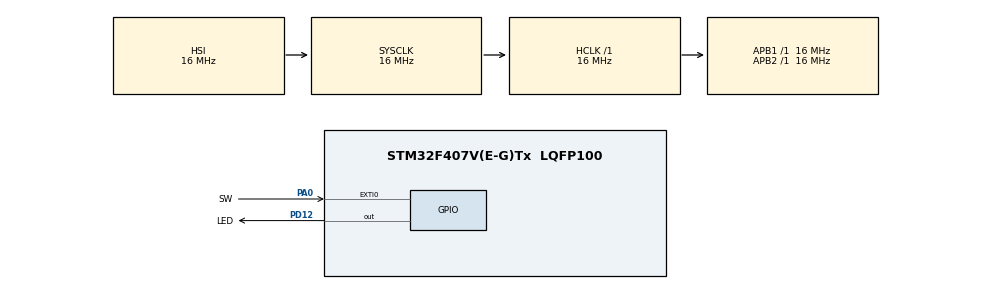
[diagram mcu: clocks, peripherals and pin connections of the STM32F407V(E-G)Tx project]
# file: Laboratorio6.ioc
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Mcu.Family=STM32F4
Mcu.Name=STM32F407V(E-G)Tx
Mcu.Package=LQFP100
NVIC.EXTI0_IRQn=true\:0\:0\:false\:false\:true\:true\:true\:true
NVIC.PriorityGroup=NVIC_PRIORITYGROUP_4
PA0-WKUP.GPIO_Label=SW
PA0-WKUP.GPIO_ModeDefaultEXTI=GPIO_MODE_IT_FALLING
PA0-WKUP.Signal=GPXTI0
PD12.GPIO_Label=LED
PD12.Signal=GPIO_Output
ProjectManager.HeapSize=0x200
ProjectManager.StackSize=0x400
ProjectManager.TargetToolchain=STM32CubeIDE
RCC.AHBFreq_Value=16000000
RCC.APB1Freq_Value=16000000
RCC.APB2Freq_Value=16000000
RCC.CortexFreq_Value=16000000
RCC.HSE_VALUE=25000000
RCC.HSI_VALUE=16000000
RCC.LSE_VALUE=32768
RCC.SYSCLKFreq_VALUE=16000000
RCC.VCOOutputFreq_Value=192000000
board=custom

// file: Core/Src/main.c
/* USER CODE BEGIN Header */
/**
 ******************************************************************************
 * @file           : main.c
 * @brief          : Main program body
 ******************************************************************************
 * @attention
 *
 * Copyright (c) 2026 STMicroelectronics.
 * All rights reserved.
 *
 * This software is licensed under terms that can be found in the LICENSE file
 * in the root directory of this software component.
 * If no LICENSE file comes with this software, it is provided AS-IS.
 *
 ******************************************************************************
 */
/* USER CODE END Header */
#include "main.h"

/* USER CODE BEGIN Includes */
#include "Statechart_required.h"
#include <stdbool.h>
/* USER CODE END Includes */

/* USER CODE BEGIN PD */
#define T_REBOTE_MS 50U
/* USER CODE END PD */

/* USER CODE BEGIN PV */
Statechart mi_maquina;
volatile bool sw = false;
volatile uint32_t last_sw = 0;

uint32_t sc_timer_start = 0;
uint32_t sc_timer_delay = 0;
bool sc_timer_active = false;
sc_eventid sc_active_evid = NULL;
/* USER CODE END PV */

void SystemClock_Config(void);
static void MX_GPIO_Init(void);

int main(void)
{

	/* USER CODE BEGIN 1 */
	uint32_t current_time = 0;
	/* USER CODE END 1 */

	/* MCU Configuration--------------------------------------------------------*/

	/* Reset of all peripherals, Initializes the Flash interface and the Systick. */
	HAL_Init();

	/* Configure the system clock */
	SystemClock_Config();

	/* Initialize all configured peripherals */
	MX_GPIO_Init();
	/* USER CODE BEGIN 2 */
	statechart_init(&mi_maquina);
	statechart_enter(&mi_maquina);
	/* USER CODE END 2 */

	/* Infinite loop */
	while (1)
	{
		if(sc_timer_active && ((HAL_GetTick()-sc_timer_start)>= sc_timer_delay))
		{
			sc_timer_active = false;
			statechart_raise_time_event(&mi_maquina, sc_active_evid);
		}
		if(sw)
		{
			current_time = HAL_GetTick();
			if(current_time-last_sw > T_REBOTE_MS)
			{
				if(HAL_GPIO_ReadPin(SW_GPIO_Port, SW_Pin) == GPIO_PIN_RESET)
				{
					statechartIface_raise_pulsacion(&mi_maquina);
				}
				sw = false;
				__HAL_GPIO_EXTI_CLEAR_IT(SW_Pin);
				HAL_NVIC_ClearPendingIRQ(EXTI0_IRQn);
				HAL_NVIC_EnableIRQ(EXTI0_IRQn);
			}
		}
		bool encender_led = statechartIface_get_led_encendido(&mi_maquina);
		if (encender_led)
		{
			HAL_GPIO_WritePin(LED_GPIO_Port, LED_Pin, GPIO_PIN_SET);
		}
		else
		{
			HAL_GPIO_WritePin(LED_GPIO_Port, LED_Pin, GPIO_PIN_RESET);
		}
	}
}

void SystemClock_Config(void)
{
	RCC_OscInitTypeDef RCC_OscInitStruct = {0};
	RCC_ClkInitTypeDef RCC_ClkInitStruct = {0};

	/** Configure the main internal regulator output voltage
	 */
	__HAL_RCC_PWR_CLK_ENABLE();
	__HAL_PWR_VOLTAGESCALING_CONFIG(PWR_REGULATOR_VOLTAGE_SCALE1);

	/** Initializes the RCC Oscillators according to the specified parameters
	 * in the RCC_OscInitTypeDef structure.
	 */
	RCC_OscInitStruct.OscillatorType = RCC_OSCILLATORTYPE_HSI;
	RCC_OscInitStruct.HSIState = RCC_HSI_ON;
	RCC_OscInitStruct.HSICalibrationValue = RCC_HSICALIBRATION_DEFAULT;
	RCC_OscInitStruct.PLL.PLLState = RCC_PLL_NONE;
	if (HAL_RCC_OscConfig(&RCC_OscInitStruct) != HAL_OK)
	{
		Error_Handler();
	}

	/** Initializes the CPU, AHB and APB buses clocks
	 */
	RCC_ClkInitStruct.ClockType = RCC_CLOCKTYPE_HCLK|RCC_CLOCKTYPE_SYSCLK
			|RCC_CLOCKTYPE_PCLK1|RCC_CLOCKTYPE_PCLK2;
	RCC_ClkInitStruct.SYSCLKSource = RCC_SYSCLKSOURCE_HSI;
	RCC_ClkInitStruct.AHBCLKDivider = RCC_SYSCLK_DIV1;
	RCC_ClkInitStruct.APB1CLKDivider = RCC_HCLK_DIV1;
	RCC_ClkInitStruct.APB2CLKDivider = RCC_HCLK_DIV1;

	if (HAL_RCC_ClockConfig(&RCC_ClkInitStruct, FLASH_LATENCY_0) != HAL_OK)
	{
		Error_Handler();
	}
}

static void MX_GPIO_Init(void)
{
	GPIO_InitTypeDef GPIO_InitStruct = {0};

	/* GPIO Ports Clock Enable */
	__HAL_RCC_GPIOA_CLK_ENABLE();
	__HAL_RCC_GPIOD_CLK_ENABLE();

	/*Configure GPIO pin Output Level */
	HAL_GPIO_WritePin(LED_GPIO_Port, LED_Pin, GPIO_PIN_RESET);

	/*Configure GPIO pin : SW_Pin */
	GPIO_InitStruct.Pin = SW_Pin;
	GPIO_InitStruct.Mode = GPIO_MODE_IT_FALLING;
	GPIO_InitStruct.Pull = GPIO_NOPULL;
	HAL_GPIO_Init(SW_GPIO_Port, &GPIO_InitStruct);

	/*Configure GPIO pin : LED_Pin */
	GPIO_InitStruct.Pin = LED_Pin;
	GPIO_InitStruct.Mode = GPIO_MODE_OUTPUT_PP;
	GPIO_InitStruct.Pull = GPIO_NOPULL;
	GPIO_InitStruct.Speed = GPIO_SPEED_FREQ_LOW;
	HAL_GPIO_Init(LED_GPIO_Port, &GPIO_InitStruct);

	/* EXTI interrupt init*/
	HAL_NVIC_SetPriority(EXTI0_IRQn, 0, 0);
	HAL_NVIC_EnableIRQ(EXTI0_IRQn);

}

/* USER CODE BEGIN 4 */
void HAL_GPIO_EXTI_Callback(uint16_t GPIO_Pin)
{
	if(GPIO_Pin == SW_Pin)
	{
		HAL_NVIC_DisableIRQ(EXTI0_IRQn);
		last_sw = HAL_GetTick();
		sw = true;
	}
}

void statechart_set_timer(Statechart* handle, const sc_eventid evid, const sc_time time_ms, const sc_boolean periodic)
{
	sc_active_evid = evid;
	sc_timer_delay = time_ms;
	sc_timer_start = HAL_GetTick();
	sc_timer_active = true;
}

void statechart_unset_timer(Statechart* handle, const sc_eventid evid)
{
	sc_timer_active = false;
}
/* USER CODE END 4 */

void Error_Handler(void)
{
	__disable_irq();
	while (1)
	{
	}
}
